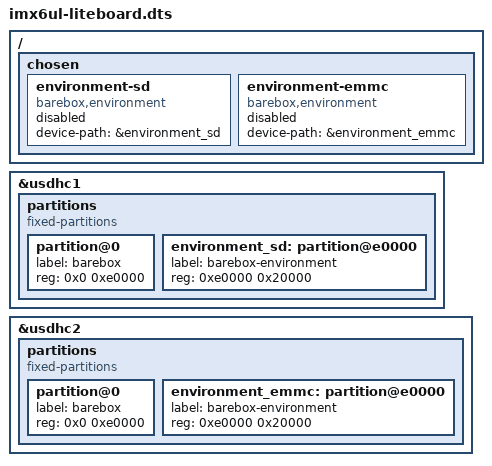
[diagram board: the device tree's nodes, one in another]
/*
 * Copyright 2018 Grinn
 *
 * Author: Marcin Niestroj <m.niestroj@grinn-global.com>
 *
 * This file is dual-licensed: you can use it either under the terms
 * of the GPL or the X11 license, at your option. Note that this dual
 * licensing only applies to this file, and not this project as a
 * whole.
 *
 *  a) This file is free software; you can redistribute it and/or
 *     modify it under the terms of the GNU General Public License
 *     version 2 as published by the Free Software Foundation.
 *
 *     This file is distributed in the hope that it will be useful,
 *     but WITHOUT ANY WARRANTY; without even the implied warranty of
 *     MERCHANTABILITY or FITNESS FOR A PARTICULAR PURPOSE.  See the
 *     GNU General Public License for more details.
 *
 * Or, alternatively,
 *
 *  b) Permission is hereby granted, free of charge, to any person
 *     obtaining a copy of this software and associated documentation
 *     files (the "Software"), to deal in the Software without
 *     restriction, including without limitation the rights to use,
 *     copy, modify, merge, publish, distribute, sublicense, and/or
 *     sell copies of the Software, and to permit persons to whom the
 *     Software is furnished to do so, subject to the following
 *     conditions:
 *
 *     The above copyright notice and this permission notice shall be
 *     included in all copies or substantial portions of the Software.
 *
 *     THE SOFTWARE IS PROVIDED "AS IS", WITHOUT WARRANTY OF ANY KIND,
 *     EXPRESS OR IMPLIED, INCLUDING BUT NOT LIMITED TO THE WARRANTIES
 *     OF MERCHANTABILITY, FITNESS FOR A PARTICULAR PURPOSE AND
 *     NONINFRINGEMENT. IN NO EVENT SHALL THE AUTHORS OR COPYRIGHT
 *     HOLDERS BE LIABLE FOR ANY CLAIM, DAMAGES OR OTHER LIABILITY,
 *     WHETHER IN AN ACTION OF CONTRACT, TORT OR OTHERWISE, ARISING
 *     FROM, OUT OF OR IN CONNECTION WITH THE SOFTWARE OR THE USE OR
 *     OTHER DEALINGS IN THE SOFTWARE.
 */

#include <arm/imx6ul-liteboard.dts>

/ {
	chosen {
		environment-sd {
			compatible = "barebox,environment";
			device-path = &environment_sd;
			status = "disabled";
		};

		environment-emmc {
			compatible = "barebox,environment";
			device-path = &environment_emmc;
			status = "disabled";
		};
	};
};

&usdhc1 {
	partitions {
		compatible = "fixed-partitions";
		#address-cells = <1>;
		#size-cells = <1>;

		partition@0 {
			label = "barebox";
			reg = <0x0 0xe0000>;
		};

		environment_sd: partition@e0000 {
			label = "barebox-environment";
			reg = <0xe0000 0x20000>;
		};
	};
};

&usdhc2 {
	partitions {
		compatible = "fixed-partitions";
		#address-cells = <1>;
		#size-cells = <1>;

		partition@0 {
			label = "barebox";
			reg = <0x0 0xe0000>;
		};

		environment_emmc: partition@e0000 {
			label = "barebox-environment";
			reg = <0xe0000 0x20000>;
		};
	};
};
